# va416xx register map
Vendor: VORAGO TECHNOLOGIES; Series: M4; File version: 1.3
CPU: CM4 r0p1, little endian, no MPU, FPU, 3 interrupt priority bits
Registers are 32-bit, read-write, reset 0x0 unless marked. A register's access mark holds for its fields unless they carry their own. Offsets are from the block's base; [hi:lo] are bit positions; {n}, {i} and the like mark numbered series; 'fields as' and 'values as' point back to an identical list.

## CLKGEN — Clock Generation Peripheral
Base 0x40006000
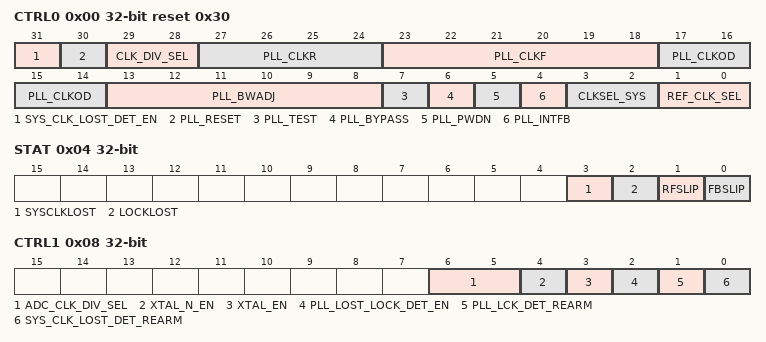
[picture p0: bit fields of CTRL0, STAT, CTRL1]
0x00 CTRL0 reset 0x30 — Clock Generation Module Control Register 0
  [31] SYS_CLK_LOST_DET_EN — Enable the circuit that detects loss of SYS_CLK
  [30] PLL_RESET — Writing this bit to 1 puts the PLL into reset
  [29:28] CLK_DIV_SEL — Selects the PLL out divider to divide by 1/2/4/8
  [27:24] PLL_CLKR — PLL Symbol; selects the values 1-16 for the reference divider
  [23:18] PLL_CLKF — PLL Symbol; selects the values 1-64 for the multiplication factor
  [17:14] PLL_CLKOD — PLL Symbol; selects the values 1-16 for the post VCO divider
  [13:8] PLL_BWADJ — PLL Symbol; selects the values 1-64 for the bandwidth divider
  [7] PLL_TEST — PLL Symbol; Reference-to-counters-to-output bypass when high
  [6] PLL_BYPASS — PLL Symbol; reference-to-output bypass when high
  [5] PLL_PWDN — PLL Symbol; power down when high
  [4] PLL_INTFB — PLL Symbol; select internal feedback path when high rather than FCLK
  [3:2] CLKSEL_SYS — Input clock select to PLL
  [1:0] REF_CLK_SEL — PLL Reference Clock Select
0x04 STAT ro — Clock Generation Module Status Register
  [3] SYSCLKLOST — Set when SYS_CLK has dropped to less than 1MHz
  [2] LOCKLOST — LOCK high Symbol indicates that RFLSIP or FBSLIP have occurred for 64 consecutive cycles
  [1] RFSLIP — Reference cycle slip output (CLKOUT frequency high)
  [0] FBSLIP — Feedback cycle slip output (CLKOUT frequency low)
0x08 CTRL1 — Clock Generation Module Control Register 1
  [6:5] ADC_CLK_DIV_SEL — Clock divider select for ADC
  [4] XTAL_N_EN — Enables XTAL_N output
  [3] XTAL_EN — Enables the crystal oscillator
  [2] PLL_LOST_LOCK_DET_EN — Enables the PLL lock lost detection circuit
  [1] PLL_LCK_DET_REARM — Resets/Rearms the PLL lock detect circuit
  [0] SYS_CLK_LOST_DET_REARM — Resets/Rearms the SYS_CLK lost detection feature

## IOCONFIG — IO Pin Configuration Peripheral
Base 0x40011000
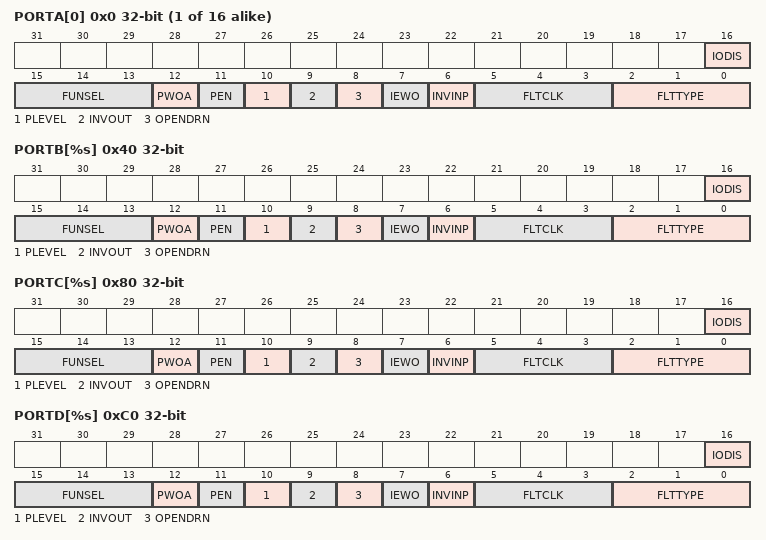
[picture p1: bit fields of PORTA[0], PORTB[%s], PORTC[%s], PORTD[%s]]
{0x0+4i} PORTA[{i}] (i=0..15) — PORTA Pin Configuration Register
  [16] IODIS — IO Pin Disable
  [15:13] FUNSEL — Pin Function Selection
  [12] PWOA — Enable Pull when output active
  [11] PEN — Enable Internal Pull up/down
  [10] PLEVEL — Internal Pull up/down level
  [9] INVOUT — Output Invert Selection
  [8] OPENDRN — Output Open Drain Mode
  [7] IEWO — Input Enable While Output enabled
  [6] INVINP — Input Invert Selection
  [5:3] FLTCLK — Input Filter Clock Selection
  [2:0] FLTTYPE — Input Filter Selectoin
    0=SYNC (Synchronize to system clock); 1=DIRECT (Direct input, no synchronization); {v}=FILTER{v-1} (Require {v} samples to have the same value) (v=2..5)
0x40 PORTB[%s] — PORTB Pin Configuration Register
  fields as PORTA[0]
0x80 PORTC[%s] — PORTC Pin Configuration Register
  fields as PORTA[0]
0xC0 PORTD[%s] — PORTD Pin Configuration Register
  fields as PORTA[0]
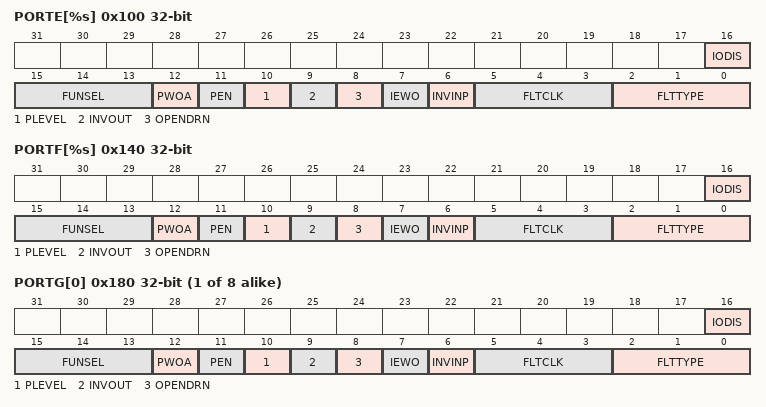
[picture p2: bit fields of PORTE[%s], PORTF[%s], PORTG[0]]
0x100 PORTE[%s] — PORTE Pin Configuration Register
  fields as PORTA[0]
0x140 PORTF[%s] — PORTF Pin Configuration Register
  fields as PORTA[0]
{0x180+4i} PORTG[{i}] (i=0..7) — PORTG Pin Configuration Register
  fields as PORTA[0]
0x1C0 CLKDIV0 ro — Clock divide value. 0 will disable the clock
{0x1C0+4i} CLKDIV{i} (i=1..7) — Clock divide value. 0 will disable the clock
0xFFC PERID ro reset 0x28207E9 — Peripheral ID Register

## UTILITY — Utility Peripheral
Base 0x40020000
0x00 SYND_DATA — Data Register
0x04 SYND_SYND — Syndrome Data Register
  [11:0] SYND_SYND — Provides bits 11:0 for syndrome, 2x6-bit
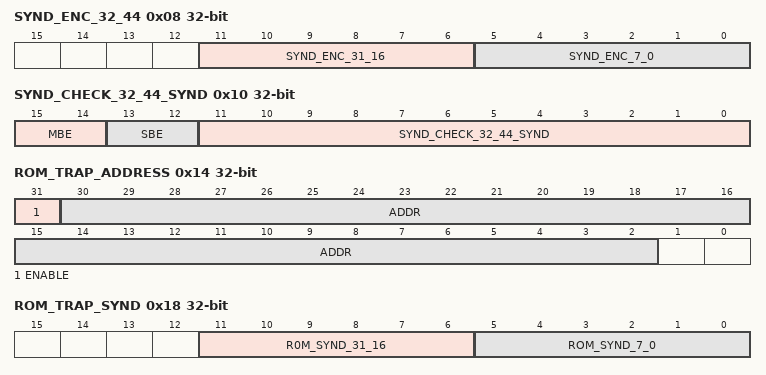
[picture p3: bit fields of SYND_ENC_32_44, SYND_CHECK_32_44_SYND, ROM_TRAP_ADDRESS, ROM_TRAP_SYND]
0x08 SYND_ENC_32_44 — EDAC Encode
  [11:6] SYND_ENC_31_16 — Computed syndrome value for bits 31-16
  [5:0] SYND_ENC_7_0 — Computed syndrome value for bits 15-0
0x0C SYND_CHECK_32_44_DATA ro — EDAC Decode Data
0x10 SYND_CHECK_32_44_SYND ro — EDAC Decode Syndrome
  [15:14] MBE — Multiple bit error detect status
  [13:12] SBE — Single bit error detect status
  [11:0] SYND_CHECK_32_44_SYND — Correct syndrome value
0x14 ROM_TRAP_ADDRESS — ROM EDAC Trap Address
  [31] ENABLE — Enable Trap mode
  [30:2] ADDR — Address bits for trap match
0x18 ROM_TRAP_SYND — ROM EDAC Trap Syndrome
  [11:6] R0M_SYND_31_16 — 6-bit syndrome value for bits 31-16
  [5:0] ROM_SYND_7_0 — 6-bit syndrome value for bits 15-0
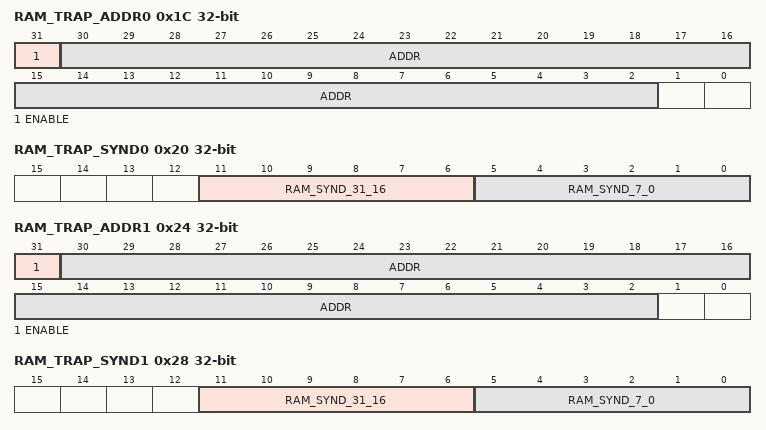
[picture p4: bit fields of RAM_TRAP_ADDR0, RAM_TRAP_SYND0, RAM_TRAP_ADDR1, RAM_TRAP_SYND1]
0x1C RAM_TRAP_ADDR0 — RAM0 EDAC Trap Address
  fields as ROM_TRAP_ADDRESS
0x20 RAM_TRAP_SYND0 — RAM0 EDAC Trap Syndrome
  [11:6] RAM_SYND_31_16 — 6-bit syndrome value for bits 31-16
  [5:0] RAM_SYND_7_0 — 6-bit syndrome value for bits 15-0
0x24 RAM_TRAP_ADDR1 — RAM1 EDAC Trap Address
  fields as ROM_TRAP_ADDRESS
0x28 RAM_TRAP_SYND1 — RAM1 EDAC Trap Syndrome
  fields as RAM_TRAP_SYND0
0x120 SYND_ENC_32_52 ro — EDAC Encode
  [19:0] SYND_ENC_32_52 — Computed syndrome value for bits 15-0
0x124 SYND_CHECK_32_52_DATA ro — EDAC Decode Data
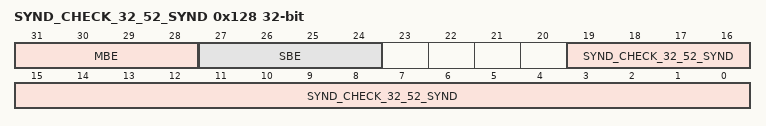
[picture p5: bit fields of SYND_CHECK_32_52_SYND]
0x128 SYND_CHECK_32_52_SYND ro — EDAC Decode Syndrome
  [31:28] MBE — Multiple bit error detect status
  [27:24] SBE — Single bit error detect status
  [19:0] SYND_CHECK_32_52_SYND — Corrected syndrome value
0xFFC PERID ro reset 0x28407E9 — Peripheral ID Register

## Notices in the file
Copyright (c) 2013-2020 VORAGO Technologies
BY DOWNLOADING, INSTALLING OR USING THIS SOFTWARE, YOU AGREE TO BE BOUND BY ALL THE TERMS
AND CONDITIONS OF THE VORAGO TECHNOLOGIES END USER LICENSE AGREEMENT.
THIS SOFTWARE IS PROVIDED "AS IS".  NO WARRANTIES, WHETHER EXPRESS, IMPLIED
OR STATUTORY, INCLUDING, BUT NOT LIMITED TO, IMPLIED WARRANTIES OF
MERCHANTABILITY AND FITNESS FOR A PARTICULAR PURPOSE APPLY TO THIS SOFTWARE.
VORAGO TECHNOLOGIES SHALL NOT, IN ANY CIRCUMSTANCES, BE LIABLE
FOR SPECIAL, INCIDENTAL, OR CONSEQUENTIAL DAMAGES, FOR ANY REASON WHATSOEVER.
